# MKE04Z4 register map
Vendor: NXP Semiconductors; Series: Kinetis_E; File version: 1.6
CPU: CM0PLUS r0p0, little endian, no MPU, no FPU, VTOR, 2 interrupt priority bits
Registers are 32-bit, read-write, reset 0x0 unless marked. A register's access mark holds for its fields unless they carry their own. Offsets are from the block's base; [hi:lo] are bit positions; {n}, {i} and the like mark numbered series.

## GPIOA — General Purpose Input/Output
Base 0x400FF000; register names take the prefix GPIOA_
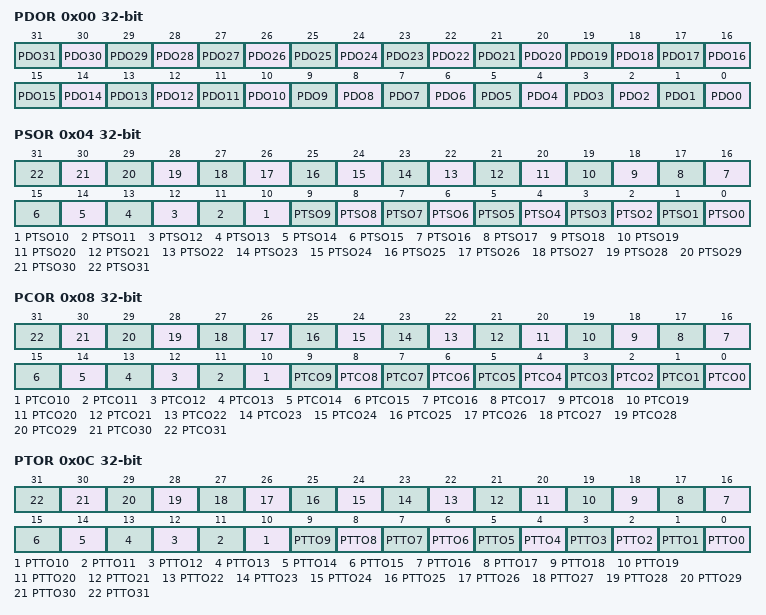
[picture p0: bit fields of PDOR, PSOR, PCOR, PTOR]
0x00 PDOR — Port Data Output Register
  [all] fields
    0=Logic level 0 is driven on pin, provided pin is configured for general-purpose output; 1=Logic level 1 is driven on pin, provided pin is configured for general-purpose output
  [n] PDO{n} (n=0..31) — Port Data Output
0x04 PSOR wo — Port Set Output Register
  [all] fields
    0=Corresponding bit in PDORn does not change; 1=Corresponding bit in PDORn is set to logic 1
  [n] PTSO{n} (n=0..31) — Port Set Output
0x08 PCOR wo — Port Clear Output Register
  [all] fields
    0=Corresponding bit in PDORn does not change; 1=Corresponding bit in PDORn is cleared to logic 0
  [n] PTCO{n} (n=0..31) — Port Clear Output
0x0C PTOR wo — Port Toggle Output Register
  [all] fields
    0=Corresponding bit in PDORn does not change; 1=Corresponding bit in PDORn is set to the inverse of its existing logic state
  [n] PTTO{n} (n=0..31) — Port Toggle Output
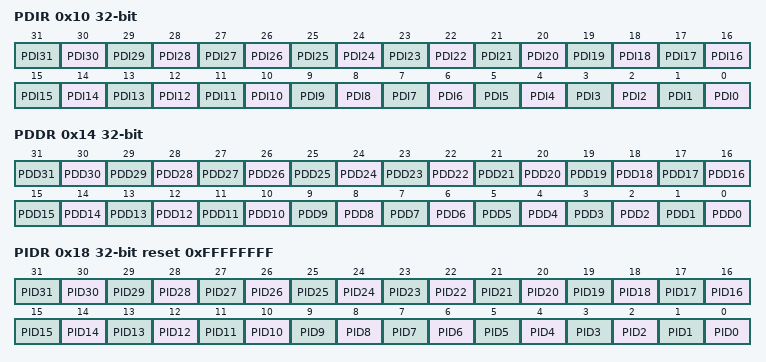
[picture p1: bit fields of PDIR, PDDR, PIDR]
0x10 PDIR ro — Port Data Input Register
  [all] fields
    0=Pin logic level is logic 0, or is not configured for use by digital function; 1=Pin logic level is logic 1
  [n] PDI{n} (n=0..31) — Port Data Input
0x14 PDDR — Port Data Direction Register
  [all] fields
    0=Pin is configured as general-purpose input, for the GPIO function. The pin will be high-Z if the port input is disabled in GPIOx_PIDR register.; 1=Pin is configured as general-purpose output, for the GPIO function
  [n] PDD{n} (n=0..31) — Port Data Direction
0x18 PIDR reset 0xFFFFFFFF — Port Input Disable Register
  [all] fields
    0=Pin is configured for General Purpose Input, provided the pin is configured for any digital function; 1=Pin is not configured as General Purpose Input.Corresponding Port Data Input Register bit will read zero
  [n] PID{n} (n=0..31) — Port Input Disable

## ROM — System ROM
Base 0xF0002000; register names take the prefix ROM_
0x00 ENTRY ro reset not defined
0x04 TABLEMARK ro — End of Table Marker Register
  [31:0] MARK — Hardwired to 0x0000_0000
0xFCC SYSACCESS ro reset 0x1 — System Access Register
  [31:0] SYSACCESS — Hardwired to 0x0000_0001
0xFD0 PERIPHID{x} (x=4,5,6,7,0,1,2,3; step 0x4) ro reset not defined — Peripheral ID Register
  [31:0] PERIPHID — Peripheral ID1 is hardwired to 0x0000_00E0; ID2 to 0x0000_0008; and all the others to 0x0000_0000.
{0xFF0+4i} COMPID{i} (i=0..3) ro reset not defined — Component ID Register
  [31:0] COMPID — Component ID

## MCM — Core Platform Miscellaneous Control Module
Base 0xF0003000; register names take the prefix MCM_
0x08 PLASC 16-bit ro reset 0x7 — Crossbar Switch (AXBS) Slave Configuration
  [7:0] ASC — Each bit in the ASC field indicates whether there is a corresponding connection to the crossbar switch's slave input port.
    0=A bus slave connection to AXBS input port n is absent; 1=A bus slave connection to AXBS input port n is present
0x0A PLAMC 16-bit ro reset 0x1 — Crossbar Switch (AXBS) Master Configuration
  [7:0] AMC — Each bit in the AMC field indicates whether there is a corresponding connection to the AXBS master input port.
    0=A bus master connection to AXBS input port n is absent; 1=A bus master connection to AXBS input port n is present
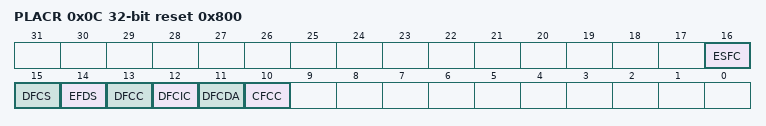
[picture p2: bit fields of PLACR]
0x0C PLACR reset 0x800 — Platform Control Register
  [16] ESFC — Enable Stalling Flash Controller
    0=Disable stalling flash controller when flash is busy; 1=Enable stalling flash controller when flash is busy
  [15] DFCS — Disable Flash Controller Speculation
    0=Enable flash controller speculation; 1=Disable flash controller speculation
  [14] EFDS — Enable Flash Data Speculation
    0=Disable flash data speculation; 1=Enable flash data speculation
  [13] DFCC — Disable Flash Controller Cache
    0=Enable flash controller cache; 1=Disable flash controller cache
  [12] DFCIC — Disable Flash Controller Instruction Caching
    0=Enable flash controller instruction caching; 1=Disable flash controller instruction caching
  [11] DFCDA — Disable Flash Controller Data Caching
    0=Enable flash controller data caching; 1=Disable flash controller data caching
  [10] CFCC wo — Clear Flash Controller Cache

## FGPIOA — General Purpose Input/Output
Base 0xF8000000; register names take the prefix FGPIOA_
0x00 PDOR — Port Data Output Register
  [31:0] PDO — Port Data Output
    0=Logic level 0 is driven on pin, provided pin is configured for general-purpose output; 1=Logic level 1 is driven on pin, provided pin is configured for general-purpose output
0x04 PSOR wo — Port Set Output Register
  [31:0] PTSO — Port Set Output
    0=Corresponding bit in PDORn does not change; 1=Corresponding bit in PDORn is set to logic 1
0x08 PCOR wo — Port Clear Output Register
  [31:0] PTCO — Port Clear Output
    0=Corresponding bit in PDORn does not change; 1=Corresponding bit in PDORn is cleared to logic 0
0x0C PTOR wo — Port Toggle Output Register
  [31:0] PTTO — Port Toggle Output
    0=Corresponding bit in PDORn does not change; 1=Corresponding bit in PDORn is set to the inverse of its existing logic state
0x10 PDIR ro — Port Data Input Register
  [31:0] PDI — Port Data Input
    0=Pin logic level is logic 0, or is not configured for use by digital function; 1=Pin logic level is logic 1
0x14 PDDR — Port Data Direction Register
  [31:0] PDD — Port Data Direction
    0=Pin is configured as general-purpose input, for the GPIO function. The pin will be high-Z if the port input is disabled in FPIOx_PIDR register.; 1=Pin is configured as general-purpose output, for the GPIO function
0x18 PIDR reset 0xFFFFFFFF — Port Input Disable Register
  [31:0] PID — Port Input Disable
    0=Pin is configured for General Purpose Input, provided the pin is configured for any digital function; 1=Pin is not configured as General Purpose Input. Corresponding Port Data Input Register bit will read zero.
